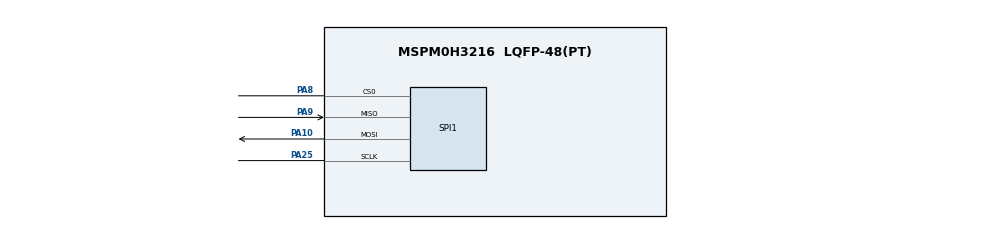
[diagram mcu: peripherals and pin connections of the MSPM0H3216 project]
//@cliArgs --device "MSPM0H3216" --package "LQFP-48(PT)" --part "Default"
//@v2CliArgs --device "MSPM0H3216" --package "LQFP-48(PT)"
// @cliArgs --board /ti/boards/LP_MSPM0H3216 --rtos nortos

/**
 * Import the modules used in this configuration.
 */
const GPIO   = scripting.addModule("/ti/driverlib/GPIO", {}, false);
const GPIO1  = GPIO.addInstance();
const SPI  = scripting.addModule("/ti/driverlib/SPI", {}, false);
const SPI1 = SPI.addInstance();

/**
 * Write custom configuration values to the imported modules.
 */

GPIO1.$name                                 = "GPIO_LEDS";
GPIO1.associatedPins.create(2);
GPIO1.associatedPins[0].$name               = "USER_LED_1";
GPIO1.associatedPins[0].assignedPort        = "PORTA";
GPIO1.associatedPins[0].assignedPortSegment = "Lower";
GPIO1.associatedPins[0].assignedPin         = "0";
GPIO1.associatedPins[0].initialValue        = "SET";
GPIO1.associatedPins[1].$name               = "USER_TEST";
GPIO1.associatedPins[1].assignedPort        = "PORTA";
GPIO1.associatedPins[1].initialValue        = "SET";
GPIO1.associatedPins[1].assignedPin         = "15";

SPI1.$name                          = "SPI_0";
SPI1.mode                           = "PERIPHERAL";
SPI1.rxFifoThreshold                = "DL_SPI_RX_FIFO_LEVEL_ONE_FRAME";
SPI1.txFifoThreshold                = "DL_SPI_TX_FIFO_LEVEL_ONE_FRAME";
SPI1.enabledDMAEvent1Triggers       = "DL_SPI_DMA_INTERRUPT_RX";
SPI1.enabledInterrupts              = ["DMA_DONE_RX"];
SPI1.peripheral.$assign         = "SPI0";
SPI1.peripheral.sclkPin.$assign = "PA25";
SPI1.peripheral.mosiPin.$assign = "PA10";
SPI1.peripheral.misoPin.$assign = "PA9";
SPI1.peripheral.cs0Pin.$assign  = "PA8";

SPI1.DMA_CHANNEL_EVENT1.$name       = "DMA_CH0";
SPI1.DMA_CHANNEL_EVENT1.addressMode = "f2b";
SPI1.DMA_CHANNEL_EVENT1.srcLength   = "BYTE";
SPI1.DMA_CHANNEL_EVENT1.dstLength   = "BYTE";
SPI1.DMA_CHANNEL_EVENT1.peripheral.$assign = "DMA_CH0";

const Board = scripting.addModule("/ti/driverlib/Board", {}, false);

const SYSCTL = scripting.addModule("/ti/driverlib/SYSCTL", {}, false);
SYSCTL.clockTreeEn = true;
SYSCTL.forceDefaultClkConfig = true;
